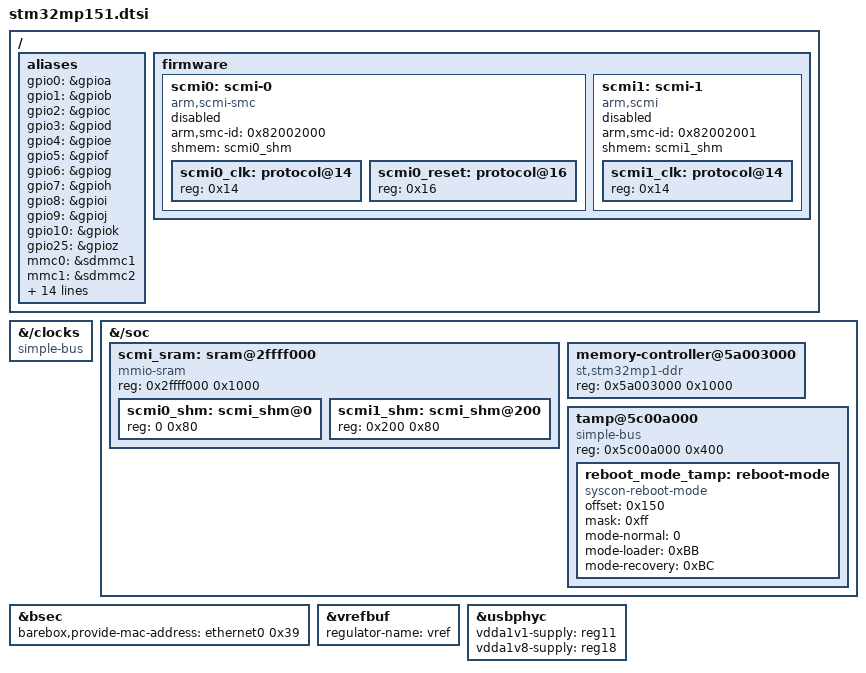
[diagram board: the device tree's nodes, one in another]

/ {
	aliases {
		gpio0 = &gpioa;
		gpio1 = &gpiob;
		gpio2 = &gpioc;
		gpio3 = &gpiod;
		gpio4 = &gpioe;
		gpio5 = &gpiof;
		gpio6 = &gpiog;
		gpio7 = &gpioh;
		gpio8 = &gpioi;
		gpio9 = &gpioj;
		gpio10 = &gpiok;
		gpio25 = &gpioz;
		mmc0 = &sdmmc1;
		mmc1 = &sdmmc2;
		mmc2 = &sdmmc3;
		pwm1 = &{/soc/timer@44000000/pwm};
		pwm2 = &{/soc/timer@40000000/pwm};
		pwm3 = &{/soc/timer@40001000/pwm};
		pwm4 = &{/soc/timer@40002000/pwm};
		pwm5 = &{/soc/timer@40003000/pwm};
		pwm8 = &{/soc/timer@44001000/pwm};
		pwm12 = &{/soc/timer@40006000/pwm};
		pwm13 = &{/soc/timer@40007000/pwm};
		pwm14 = &{/soc/timer@40008000/pwm};
		pwm15 = &{/soc/timer@44006000/pwm};
		pwm16 = &{/soc/timer@44007000/pwm};
		pwm17 = &{/soc/timer@44008000/pwm};
		tamp.reboot_mode = &reboot_mode_tamp;
	};

	firmware {
		scmi0: scmi-0 {
			compatible = "arm,scmi-smc";
			arm,smc-id = <0x82002000>;
			shmem = <&scmi0_shm>;
			#address-cells = <1>;
			#size-cells = <0>;
			status = "disabled"; /* To enable upon RCC[TZEN] */

			scmi0_clk: protocol@14 {
				reg = <0x14>;
				#clock-cells = <1>;
			};

			scmi0_reset: protocol@16 {
				reg = <0x16>;
				#reset-cells = <1>;
			};
		};

		scmi1: scmi-1 {
			compatible = "arm,scmi";
			arm,smc-id = <0x82002001>;
			shmem = <&scmi1_shm>;
			#address-cells = <1>;
			#size-cells = <0>;
			status = "disabled"; /* To enable upon RCC[MCKPROT] */

			scmi1_clk: protocol@14 {
				reg = <0x14>;
				#clock-cells = <1>;
			};
		};
	};
};

&{/clocks} {
	/* Needed to let barebox find the clock nodes */
	compatible = "simple-bus";
};

&{/soc} {
	scmi_sram: sram@2ffff000 {
		compatible = "mmio-sram";
		reg = <0x2ffff000 0x1000>;
		ranges = <0 0x2ffff000 0x1000>;
		#address-cells = <1>;
		#size-cells = <1>;

		scmi0_shm: scmi_shm@0 {
			reg = <0 0x80>;
		};

		scmi1_shm: scmi_shm@200 {
			reg = <0x200 0x80>;
		};
	};

	memory-controller@5a003000 {
		compatible = "st,stm32mp1-ddr";
		reg = <0x5a003000 0x1000>;
	};

	tamp@5c00a000 {
		compatible = "simple-bus", "syscon", "simple-mfd";
		reg = <0x5c00a000 0x400>;

		reboot_mode_tamp: reboot-mode {
			compatible = "syscon-reboot-mode";
			offset = <0x150>; /* reg20 */
			mask = <0xff>;
			mode-normal = <0>;
			mode-loader = <0xBB>;
			mode-recovery = <0xBC>;
		};
	};
};

&bsec {
	barebox,provide-mac-address = <&ethernet0 0x39>;
};

&vrefbuf {
	regulator-name = "vref";
};

&usbphyc {
	vdda1v1-supply = <&reg11>;
	vdda1v8-supply = <&reg18>;
};
